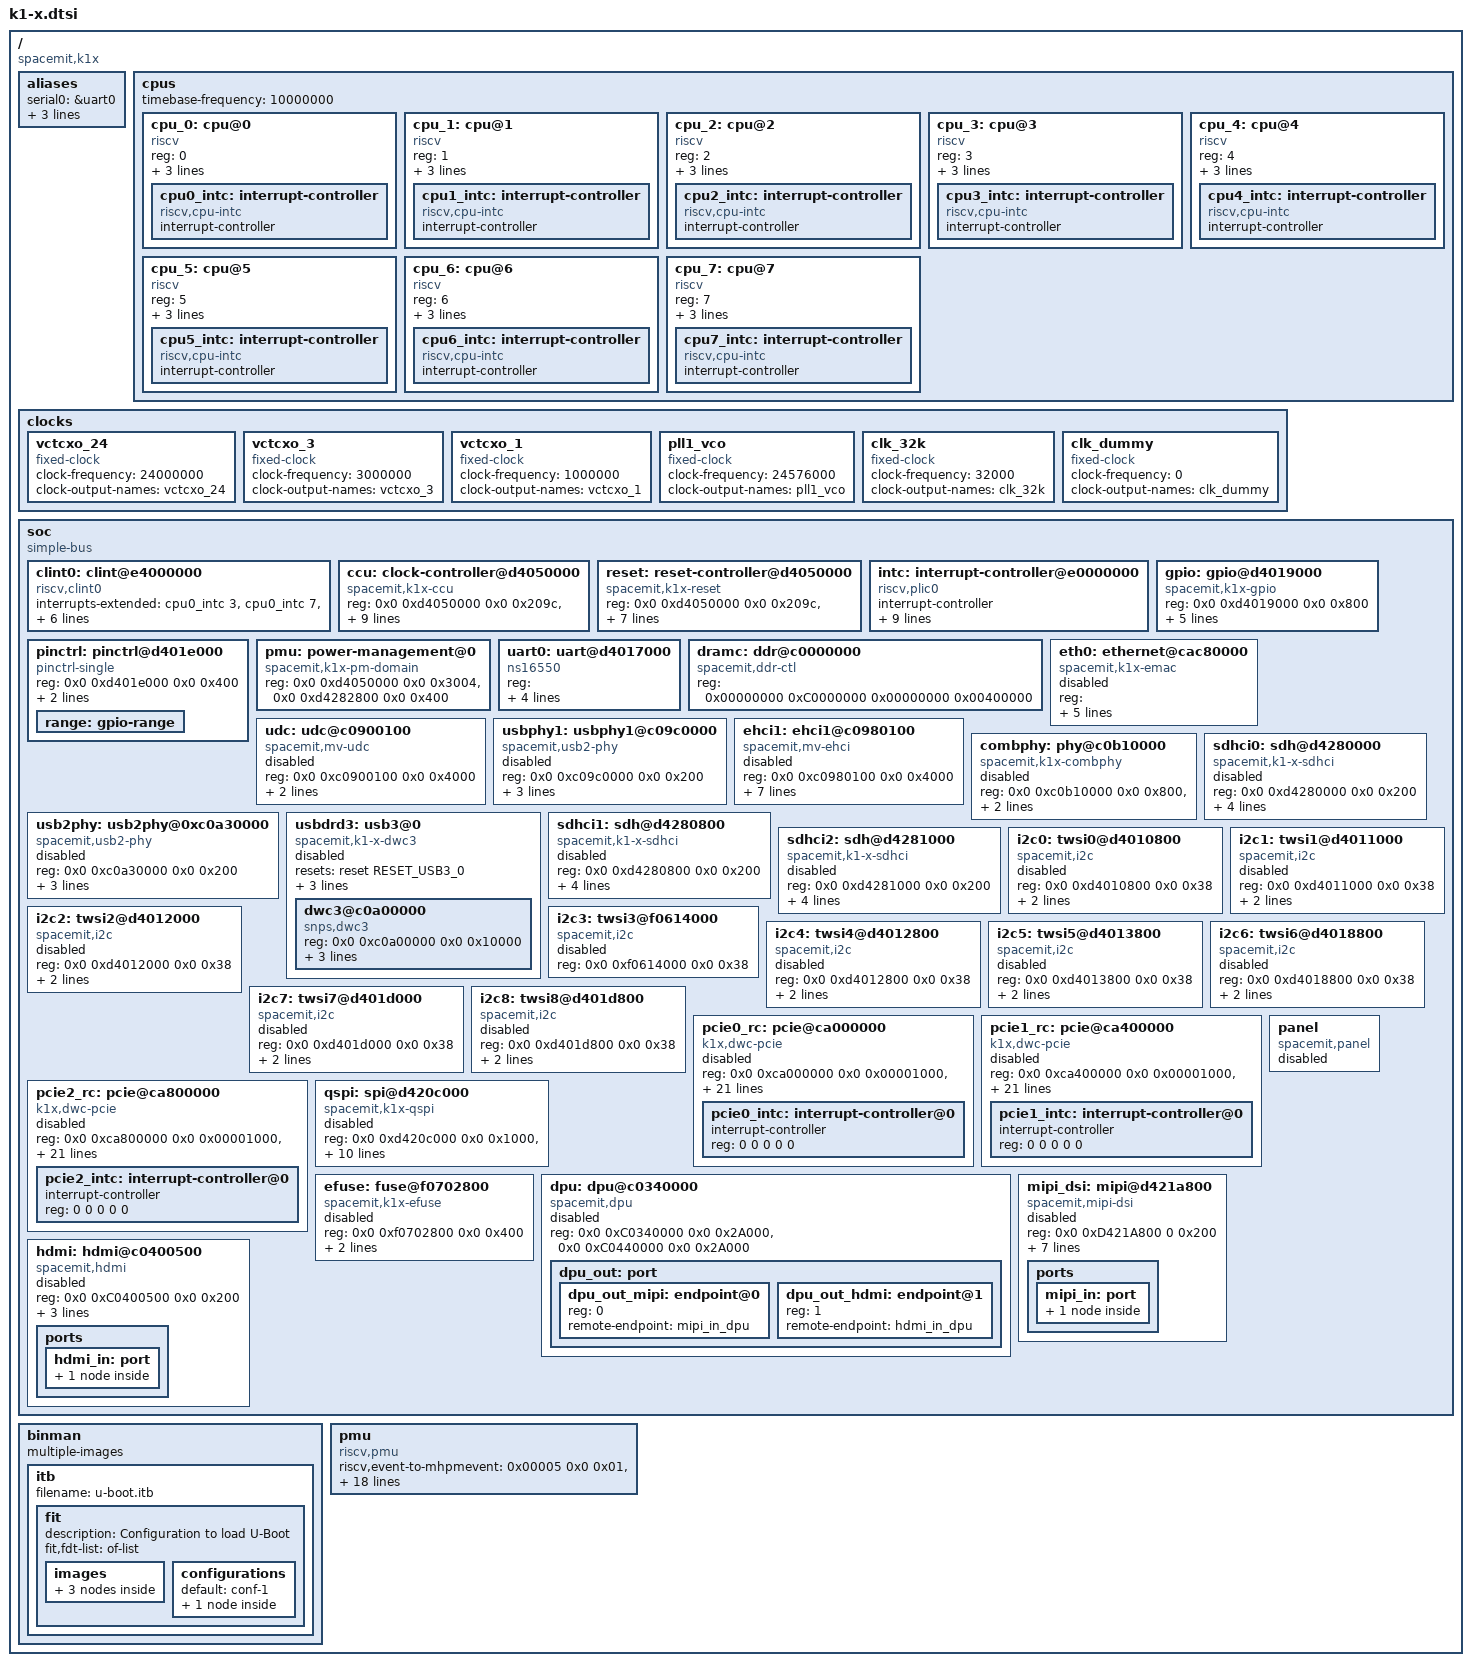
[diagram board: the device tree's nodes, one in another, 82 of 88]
// SPDX-License-Identifier: (GPL-2.0 OR MIT)
/* Copyright (c) 2023 Spacemit, Inc */

/dts-v1/;
#include <dt-bindings/reset/reset-spacemit-k1x.h>
#include <dt-bindings/clock/spacemit-k1x-clock.h>
#include <dt-bindings/power-domain/k1x-pmu.h>
#include <dt-bindings/phy/phy.h>

/ {
	compatible = "spacemit,k1x", "riscv";
	#address-cells = <2>;
	#size-cells = <2>;

	aliases {
		serial0 = &uart0;
		mmc0 = &sdhci0;
		mmc1 = &sdhci1;
		mmc2 = &sdhci2;
	};

	cpus: cpus {
		#address-cells = <1>;
		#size-cells = <0>;
		timebase-frequency = <10000000>;
		cpu_0: cpu@0 {
			compatible = "riscv";
			device_type = "cpu";
			reg = <0>;
			status = "okay";
			riscv,isa = "rv64imafdcvsu_zicsr_zifencei_zicbom_zihintpause_zba_zbb_zbc_zbs_svpbmt_sstc_sscofpmf";
			mmu-type = "riscv,sv39";

			cpu0_intc: interrupt-controller {
				#interrupt-cells = <1>;
				compatible = "riscv,cpu-intc";
				interrupt-controller;
			};
		};
		cpu_1: cpu@1 {
			compatible = "riscv";
			device_type = "cpu";
			reg = <1>;
			status = "okay";
			riscv,isa = "rv64imafdcvsu_zicsr_zifencei_zicbom_zihintpause_zba_zbb_zbc_zbs_svpbmt_sstc_sscofpmf";
			mmu-type = "riscv,sv39";

			cpu1_intc: interrupt-controller {
				#interrupt-cells = <1>;
				compatible = "riscv,cpu-intc";
				interrupt-controller;
			};
		};
		cpu_2: cpu@2 {
			compatible = "riscv";
			device_type = "cpu";
			reg = <2>;
			status = "okay";
			riscv,isa = "rv64imafdcvsu_zicsr_zifencei_zicbom_zihintpause_zba_zbb_zbc_zbs_svpbmt_sstc_sscofpmf";
			mmu-type = "riscv,sv39";

			cpu2_intc: interrupt-controller {
				#interrupt-cells = <1>;
				compatible = "riscv,cpu-intc";
				interrupt-controller;
			};
		};
		cpu_3: cpu@3 {
			compatible = "riscv";
			device_type = "cpu";
			reg = <3>;
			status = "okay";
			riscv,isa = "rv64imafdcvsu_zicsr_zifencei_zicbom_zihintpause_zba_zbb_zbc_zbs_svpbmt_sstc_sscofpmf";
			mmu-type = "riscv,sv39";

			cpu3_intc: interrupt-controller {
				#interrupt-cells = <1>;
				compatible = "riscv,cpu-intc";
				interrupt-controller;
			};
		};
		cpu_4: cpu@4 {
			compatible = "riscv";
			device_type = "cpu";
			reg = <4>;
			status = "okay";
			riscv,isa = "rv64imafdcvsu_zicsr_zifencei_zicbom_zihintpause_zba_zbb_zbc_zbs_svpbmt_sstc_sscofpmf";
			mmu-type = "riscv,sv39";

			cpu4_intc: interrupt-controller {
				#interrupt-cells = <1>;
				compatible = "riscv,cpu-intc";
				interrupt-controller;
			};
		};
		cpu_5: cpu@5 {
			compatible = "riscv";
			device_type = "cpu";
			reg = <5>;
			status = "okay";
			riscv,isa = "rv64imafdcvsu_zicsr_zifencei_zicbom_zihintpause_zba_zbb_zbc_zbs_svpbmt_sstc_sscofpmf";
			mmu-type = "riscv,sv39";

			cpu5_intc: interrupt-controller {
				#interrupt-cells = <1>;
				compatible = "riscv,cpu-intc";
				interrupt-controller;
			};
		};
		cpu_6: cpu@6 {
			compatible = "riscv";
			device_type = "cpu";
			reg = <6>;
			status = "okay";
			riscv,isa = "rv64imafdcvsu_zicsr_zifencei_zicbom_zihintpause_zba_zbb_zbc_zbs_svpbmt_sstc_sscofpmf";
			mmu-type = "riscv,sv39";

			cpu6_intc: interrupt-controller {
				#interrupt-cells = <1>;
				compatible = "riscv,cpu-intc";
				interrupt-controller;
			};
		};
		cpu_7: cpu@7 {
			compatible = "riscv";
			device_type = "cpu";
			reg = <7>;
			status = "okay";
			riscv,isa = "rv64imafdcvsu_zicsr_zifencei_zicbom_zihintpause_zba_zbb_zbc_zbs_svpbmt_sstc_sscofpmf";
			mmu-type = "riscv,sv39";

			cpu7_intc: interrupt-controller {
				#interrupt-cells = <1>;
				compatible = "riscv,cpu-intc";
				interrupt-controller;
			};
		};
	};

	clocks: clocks {
		#address-cells = <0x2>;
		#size-cells = <0x2>;
		ranges;

		vctcxo_24: vctcxo_24 {
			#clock-cells = <0>;
			compatible = "fixed-clock";
			clock-frequency = <24000000>;
			clock-output-names = "vctcxo_24";
		};
		vctcxo_3: vctcxo_3 {
			#clock-cells = <0>;
			compatible = "fixed-clock";
			clock-frequency = <3000000>;
			clock-output-names = "vctcxo_3";
		};
		vctcxo_1: vctcxo_1 {
			#clock-cells = <0>;
			compatible = "fixed-clock";
			clock-frequency = <1000000>;
			clock-output-names = "vctcxo_1";
		};
		pll1_vco: pll1_vco {
			#clock-cells = <0>;
			compatible = "fixed-clock";
			clock-frequency = <24576000>;
			clock-output-names = "pll1_vco";
		};
		clk_32k: clk_32k {
			#clock-cells = <0>;
			compatible = "fixed-clock";
			clock-frequency = <32000>;
			clock-output-names = "clk_32k";
		};
		clk_dummy: clk_dummy {
			#clock-cells = <0>;
			compatible = "fixed-clock";
			clock-frequency = <0>;
			clock-output-names = "clk_dummy";
		};
	};

	soc:soc {
		compatible = "simple-bus";
		#address-cells = <2>;
		#size-cells = <2>;
		ranges;

		clint0: clint@e4000000 {
			compatible = "riscv,clint0";
			interrupts-extended = <
				&cpu0_intc  3 &cpu0_intc  7
				&cpu1_intc  3 &cpu1_intc  7
				&cpu2_intc  3 &cpu2_intc  7
				&cpu3_intc  3 &cpu3_intc  7
				&cpu4_intc  3 &cpu4_intc  7
				&cpu5_intc  3 &cpu5_intc  7
				&cpu6_intc  3 &cpu6_intc  7
				&cpu7_intc  3 &cpu7_intc  7
			>;
			reg = <0x0 0xE4000000 0x0 0x00010000>;
		};

		ccu: clock-controller@d4050000 {
			compatible = "spacemit,k1x-ccu";
			reg = <0x0 0xd4050000 0x0 0x209c>,
				<0x0 0xd4282800 0x0 0x400>,
				<0x0 0xd4015000 0x0 0x1000>,
				<0x0 0xd4090000 0x0 0x1000>,
				<0x0 0xd4282c00 0x0 0x400>,
				<0x0 0xd8440000 0x0 0x98>,
				<0x0 0xc0000000 0x0 0x4280>,
				<0x0 0xf0610000 0x0 0x20>;
			reg-names = "mpmu", "apmu", "apbc", "apbs", "ciu", "dciu", "ddrc", "apbc2";
			clocks = <&vctcxo_24>, <&vctcxo_3>, <&vctcxo_1>, <&pll1_vco>,
				<&clk_32k>, <&clk_dummy>;
			clock-names = "vctcxo_24", "vctcxo_3", "vctcxo_1", "pll1_vco",
				"clk_32k", "clk_dummy";
			#clock-cells = <1>;
			status = "okay";
		};

		reset: reset-controller@d4050000 {
			compatible = "spacemit,k1x-reset";
			reg = <0x0 0xd4050000 0x0 0x209c>,
				<0x0 0xd4282800 0x0 0x400>,
				<0x0 0xd4015000 0x0 0x1000>,
				<0x0 0xd4090000 0x0 0x1000>,
				<0x0 0xd4282c00 0x0 0x400>,
				<0x0 0xd8440000 0x0 0x98>,
				<0x0 0xc0000000 0x0 0x4280>,
				<0x0 0xf0610000 0x0 0x20>;
			reg-names = "mpmu", "apmu", "apbc", "apbs", "ciu", "dciu", "ddrc", "apbc2";
			#reset-cells = <1>;
			status = "okay";
		};

		intc: interrupt-controller@e0000000 {
			#interrupt-cells = <1>;
			compatible = "riscv,plic0";
			interrupt-controller;
			interrupts-extended = <
				&cpu0_intc 11 &cpu0_intc 9
				&cpu1_intc 11 &cpu1_intc 9
				&cpu2_intc 11 &cpu2_intc 9
				&cpu3_intc 11 &cpu3_intc 9
				&cpu4_intc 11 &cpu4_intc 9
				&cpu5_intc 11 &cpu5_intc 9
				&cpu6_intc 11 &cpu6_intc 9
				&cpu7_intc 11 &cpu7_intc 9
			>;
			reg = <0x0 0xE0000000 0x0 0x04000000>;
			reg-names = "control";
			riscv,max-priority = <7>;
			riscv,ndev = <159>;
		};

		gpio: gpio@d4019000 {
			compatible = "spacemit,k1x-gpio";
			reg = <0x0 0xd4019000 0x0 0x800>;
			gpio-controller;
			gpio-count = <128>;
			#gpio-cells = <2>;
			interrupts = <58>;
			clocks = <&ccu CLK_GPIO>;
			interrupt-names = "gpio_mux";
			interrupt-parent = <&intc>;
		};

		pinctrl: pinctrl@d401e000 {
			compatible = "pinctrl-single";
			reg = <0x0 0xd401e000 0x0 0x400>;
			#address-cells = <1>;
			#size-cells = <1>;
			#pinctrl-cells = <2>;
			#gpio-range-cells = <3>;

			pinctrl-single,register-width = <32>;
			pinctrl-single,function-mask = <0xff77>;

			range: gpio-range {
				#pinctrl-single,gpio-range-cells = <3>;
			};
		};

                pmu: power-management@0 {
			compatible = "spacemit,k1x-pm-domain";
			reg = <0x0 0xd4050000 0x0 0x3004>, <0x0 0xd4282800 0x0 0x400>;
			#power-domain-cells = <1>;
                };

		uart0: uart@d4017000 {
			compatible = "ns16550";
			reg = <0x00000000 0xD4017000 0x00000000 0x00000100>;
			reg-shift = <2>;
			reg-io-width = <4>;
			clock-frequency = <14000000>;
		};

		dramc: ddr@c0000000 {
			compatible = "spacemit,ddr-ctl";
			reg = <0x00000000 0xC0000000 0x00000000 0x00400000>;
		};

		eth0: ethernet@cac80000 {
			compatible = "spacemit,k1x-emac";
			reg = <0x00000000 0xCAC80000 0x00000000 0x00000420>;
			ctrl-reg = <0x3e4>;
			dline-reg = <0x3e8>;
			clocks = <&ccu CLK_EMAC0_BUS>;
			clock-names = "emac-clk";
			resets = <&reset RESET_EMAC0>;
			reset-names = "emac-reset";
			status = "disabled";
		};

		udc: udc@c0900100 {
			compatible = "spacemit,mv-udc";
			reg = <0x0 0xc0900100 0x0 0x4000>;
			interrupts = <105>;
			interrupt-parent = <&intc>;
			status = "disabled";
		};

		usbphy1: usbphy1@c09c0000 {
			compatible = "spacemit,usb2-phy";
			reg = <0x0 0xc09c0000 0x0 0x200>;
			spacemit,phy-name = "mv-usb-phy";
			spacemit,pll-lock-bypass;
			clocks = <&ccu CLK_USB_P1>;
			#phy-cells = <0>;
			status = "disabled";
		};

		ehci1: ehci1@c0980100 {
			compatible = "spacemit,mv-ehci";
			reg = <0x0 0xc0980100 0x0 0x4000>;
			interrupts = <118>;
			interrupt-parent = <&intc>;
			spacemit,ehci-name = "mv-ehci";
			spacemit,otg-force-a-bus-req;
			resets = <&reset RESET_USBP1_AXI>;
			clocks = <&ccu CLK_USB_P1>;
			phys = <&usbphy1>;
			status = "disabled";
		};

		combphy: phy@c0b10000{
			compatible = "spacemit,k1x-combphy";
			reg = <0x0 0xc0b10000 0x0 0x800>,
				  <0x0 0xd4282910 0x0 0x400>;
			reg-names = "puphy", "phy_sel";
			resets = <&reset RESET_PCIE0>;
			reset-names = "phy_rst";
			#phy-cells = <1>;
			status = "disabled";
		};

		usb2phy: usb2phy@0xc0a30000 {
			compatible = "spacemit,usb2-phy";
			reg = <0x0 0xc0a30000  0x0 0x200>;
			spacemit,phy-name = "mv-usb-phy";
			spacemit,pll-lock-bypass;
			clocks = <&ccu CLK_USB30>;
			#phy-cells = <0>;
			status = "disabled";
		};

		usbdrd3: usb3@0 {
			compatible = "spacemit,k1-x-dwc3";
			#address-cells = <2>;
			#size-cells = <2>;
			resets = <&reset RESET_USB3_0>;
			reset-names = "ctl_rst";
			clocks = <&ccu CLK_USB30>;
			clock-names = "usbdrd30";
			interrupt-parent = <&intc>;
			interrupts = <149>;
			ranges;
			status = "disabled";

			dwc3@c0a00000 {
				compatible = "snps,dwc3";
				reg = <0x0 0xc0a00000 0x0 0x10000>;
				interrupt-parent = <&intc>;
				interrupts = <125>;
				phys = <&combphy PHY_TYPE_USB3>, <&usb2phy>;
				phy-names = "usb3-phy", "usb2-phy";
			};
		};

		sdhci0: sdh@d4280000 {
			compatible = "spacemit,k1-x-sdhci";
			reg = <0x0 0xd4280000 0x0 0x200>;
			interrupt-parent = <&intc>;
			interrupts = <99>;
			resets = <&reset RESET_SDH_AXI>,
					 <&reset RESET_SDH0>;
			reset-names = "sdh_axi", "sdh0";
			clocks = <&ccu CLK_SDH0>,
					 <&ccu CLK_SDH_AXI>;
			clock-names = "sdh-io", "sdh-core";
			status = "disabled";
		};

		sdhci1: sdh@d4280800 {
			compatible = "spacemit,k1-x-sdhci";
			reg = <0x0 0xd4280800 0x0 0x200>;
			interrupt-parent = <&intc>;
			interrupts = <100>;
			resets = <&reset RESET_SDH_AXI>,
					 <&reset RESET_SDH1>;
			reset-names = "sdh_axi", "sdh1";
			clocks = <&ccu CLK_SDH1>,
					 <&ccu CLK_SDH_AXI>;
			clock-names = "sdh-io", "sdh-core";
			status = "disabled";
		};

		sdhci2: sdh@d4281000 {
			compatible = "spacemit,k1-x-sdhci";
			reg = <0x0 0xd4281000 0x0 0x200>;
			interrupt-parent = <&intc>;
			interrupts = <101>;
			resets = <&reset RESET_SDH_AXI>,
					 <&reset RESET_SDH2>;
			reset-names = "sdh_axi", "sdh2";
			clocks = <&ccu CLK_SDH2>,
					 <&ccu CLK_SDH_AXI>;
			clock-names = "sdh-io", "sdh-core";
			status = "disabled";
		};

                i2c0: twsi0@d4010800 {
			compatible = "spacemit,i2c";
			reg = <0x0 0xd4010800 0x0 0x38>;
			clocks = <&ccu CLK_TWSI0>;
			resets = <&reset RESET_TWSI0>;
			#address-cells = <1>;
			#size-cells = <0>;
			status = "disabled";
                };

                i2c1: twsi1@d4011000 {
			compatible = "spacemit,i2c";
			reg = <0x0 0xd4011000 0x0 0x38>;
			clocks = <&ccu CLK_TWSI1>;
			resets = <&reset RESET_TWSI1>;
			#address-cells = <1>;
			#size-cells = <0>;
			status = "disabled";
                };

                i2c2: twsi2@d4012000 {
			compatible = "spacemit,i2c";
			reg = <0x0 0xd4012000 0x0 0x38>;
			clocks = <&ccu CLK_TWSI2>;
			resets = <&reset RESET_TWSI2>;
			#address-cells = <1>;
			#size-cells = <0>;
			status = "disabled";
                };

                i2c3: twsi3@f0614000 {
			compatible = "spacemit,i2c";
			reg = <0x0 0xf0614000 0x0 0x38>;
			#address-cells = <1>;
			#size-cells = <0>;
			status = "disabled";
                };

                i2c4: twsi4@d4012800 {
			compatible = "spacemit,i2c";
			reg = <0x0 0xd4012800 0x0 0x38>;
			clocks = <&ccu CLK_TWSI4>;
			resets = <&reset RESET_TWSI4>;
			#address-cells = <1>;
			#size-cells = <0>;
			status = "disabled";
                };

                i2c5: twsi5@d4013800 {
			compatible = "spacemit,i2c";
			reg = <0x0 0xd4013800 0x0 0x38>;
			clocks = <&ccu CLK_TWSI5>;
			resets = <&reset RESET_TWSI5>;
			#address-cells = <1>;
			#size-cells = <0>;
			status = "disabled";
                };

                i2c6: twsi6@d4018800 {
			compatible = "spacemit,i2c";
			reg = <0x0 0xd4018800 0x0 0x38>;
			clocks = <&ccu CLK_TWSI6>;
			resets = <&reset RESET_TWSI6>;
			#address-cells = <1>;
			#size-cells = <0>;
			status = "disabled";
                };

                i2c7: twsi7@d401d000 {
			compatible = "spacemit,i2c";
			reg = <0x0 0xd401d000 0x0 0x38>;
			clocks = <&ccu CLK_TWSI7>;
			resets = <&reset RESET_TWSI7>;
			#address-cells = <1>;
			#size-cells = <0>;
			status = "disabled";
                };

                i2c8: twsi8@d401d800 {
			compatible = "spacemit,i2c";
			reg = <0x0 0xd401d800 0x0 0x38>;
			clocks = <&ccu CLK_TWSI8>;
			resets = <&reset RESET_TWSI8>;
			#address-cells = <1>;
			#size-cells = <0>;
			status = "disabled";
                };

		pcie0_rc: pcie@ca000000 {
			compatible = "k1x,dwc-pcie";
			reg = <0x0 0xca000000 0x0 0x00001000>, /* dbi */
			      <0x0 0xca300000 0x0 0x0001ff24>, /* atu registers */
			      <0x0 0x80000000 0x0 0x00100000>, /* config space */
			      <0x0 0xd4282bcc 0x0 0x00000008>, /* k1x soc config addr */
			      <0x0 0xc0b20000 0x0 0x00001000>, /* phy ahb */
			      <0x0 0xc0b10000 0x0 0x00001000>, /* phy addr */
			      <0x0 0xd4282bcc 0x0 0x00000008>, /* conf0 addr */
			      <0x0 0xc0b10000 0x0 0x00001000>; /* phy0 addr */
			reg-names = "dbi", "atu", "config", "k1x_conf", "phy_ahb", "phy_addr", "conf0_addr", "phy0_addr";

			k1x,pcie-port = <0>;
			clocks = <&ccu CLK_PCIE0>;
			clock-names = "pcie-clk";
			resets = <&reset RESET_PCIE0>;
			reset-names = "pcie-reset";

			bus-range = <0x00 0xff>;
			max-link-speed = <2>;
			num-lanes = <1>;
			num-viewport = <8>;
			device_type = "pci";
			#address-cells = <3>;
			#size-cells = <2>;
			ranges = <0x81000000 0x0 0x80100000 0 0x80100000 0x0 0x100000>,
				 <0x82000000 0x0 0x80200000 0 0x80200000 0x0 0x0fe00000>;

			interrupts = <141>, <145>;
			interrupt-parent = <&intc>;
			#interrupt-cells = <1>;
			interrupt-map-mask = <0 0 0 0x7>;
			interrupt-map = <0000 0 0 1 &pcie0_intc 1>, /* int_a */
					<0000 0 0 2 &pcie0_intc 2>, /* int_b */
					<0000 0 0 3 &pcie0_intc 3>, /* int_c */
					<0000 0 0 4 &pcie0_intc 4>; /* int_d */
			linux,pci-domain = <0>;
			status = "disabled";
			pcie0_intc: interrupt-controller@0 {
				interrupt-controller;
				reg = <0 0 0 0 0>;
				#address-cells = <0>;
				#interrupt-cells = <1>;
			};
		};

		pcie1_rc: pcie@ca400000 {
			compatible = "k1x,dwc-pcie";
			reg = <0x0 0xca400000 0x0 0x00001000>, /* dbi */
			      <0x0 0xca700000 0x0 0x0001ff24>, /* atu registers */
			      <0x0 0x90000000 0x0 0x00100000>, /* config space */
			      <0x0 0xd4282bd4 0x0 0x00000008>, /* k1x soc config addr */
			      <0x0 0xc0c20000 0x0 0x00001000>, /* phy ahb */
			      <0x0 0xc0c10000 0x0 0x00001000>, /* phy addr */
			      <0x0 0xd4282bcc 0x0 0x00000008>, /* conf0 addr */
			      <0x0 0xc0b10000 0x0 0x00001000>; /* phy0 addr */
			reg-names = "dbi", "atu", "config", "k1x_conf", "phy_ahb", "phy_addr", "conf0_addr", "phy0_addr";

			k1x,pcie-port = <1>;
			clocks = <&ccu CLK_PCIE1>;
			clock-names = "pcie-clk";
			resets = <&reset RESET_PCIE1>;
			reset-names = "pcie-reset";

			bus-range = <0x00 0xff>;
			max-link-speed = <2>;
			num-lanes = <2>;
			num-viewport = <8>;
			device_type = "pci";
			#address-cells = <3>;
			#size-cells = <2>;
			ranges = <0x01000000 0x0 0x90100000 0 0x90100000 0x0 0x100000>,
				 <0x02000000 0x0 0x90200000 0 0x90200000 0x0 0x0fe00000>;

			interrupts = <142>, <146>;
			interrupt-parent = <&intc>;
			#interrupt-cells = <1>;
			interrupt-map-mask = <0 0 0 0x7>;
			interrupt-map = <0000 0 0 1 &pcie1_intc 1>, /* int_a */
					<0000 0 0 2 &pcie1_intc 2>, /* int_b */
					<0000 0 0 3 &pcie1_intc 3>, /* int_c */
					<0000 0 0 4 &pcie1_intc 4>; /* int_d */
			linux,pci-domain = <1>;
			status = "disabled";
			pcie1_intc: interrupt-controller@0 {
				interrupt-controller;
				reg = <0 0 0 0 0>;
				#address-cells = <0>;
				#interrupt-cells = <1>;
			};
		};

		pcie2_rc: pcie@ca800000 {
			compatible = "k1x,dwc-pcie";
			reg = <0x0 0xca800000 0x0 0x00001000>, /* dbi */
			      <0x0 0xcab00000 0x0 0x0001ff24>, /* atu registers */
			      <0x0 0xa0000000 0x0 0x00100000>, /* config space */
			      <0x0 0xd4282bdc 0x0 0x00000008>, /* k1x soc config addr */
			      <0x0 0xc0d20000 0x0 0x00001000>, /* phy ahb */
			      <0x0 0xc0d10000 0x0 0x00001000>, /* phy addr */
			      <0x0 0xd4282bcc 0x0 0x00000008>, /* conf0 addr */
			      <0x0 0xc0b10000 0x0 0x00001000>; /* phy0 addr */
			reg-names = "dbi", "atu", "config", "k1x_conf", "phy_ahb", "phy_addr", "conf0_addr", "phy0_addr";

			k1x,pcie-port = <2>;
			clocks = <&ccu CLK_PCIE2>;
			clock-names = "pcie-clk";
			resets = <&reset RESET_PCIE2>;
			reset-names = "pcie-reset";

			bus-range = <0x00 0xff>;
			max-link-speed = <2>;
			num-lanes = <2>;
			num-viewport = <8>;
			device_type = "pci";
			#address-cells = <3>;
			#size-cells = <2>;
			ranges = <0x01000000 0x0 0xa0100000 0 0xa0100000 0x0 0x100000>,
				 <0x02000000 0x0 0xa0200000 0 0xa0200000 0x0 0x16000000>;

			interrupts = <143>, <147>;
			interrupt-parent = <&intc>;
			#interrupt-cells = <1>;
			interrupt-map-mask = <0 0 0 0x7>;
			interrupt-map = <0000 0 0 1 &pcie2_intc 1>, /* int_a */
					<0000 0 0 2 &pcie2_intc 2>, /* int_b */
					<0000 0 0 3 &pcie2_intc 3>, /* int_c */
					<0000 0 0 4 &pcie2_intc 4>; /* int_d */
			linux,pci-domain = <2>;
			status = "disabled";
			pcie2_intc: interrupt-controller@0 {
				interrupt-controller;
				reg = <0 0 0 0 0>;
				#address-cells = <0>;
				#interrupt-cells = <1>;
			};
		};

		qspi: spi@d420c000 {
			compatible = "spacemit,k1x-qspi";
			#address-cells = <1>;
			#size-cells = <0>;
			reg = <0x0 0xd420c000 0x0 0x1000>,
			      <0x0 0xb8000000 0x0 0xd00000>;
			reg-names = "qspi-base", "qspi-mmap";
			qspi-sfa1ad = <0xa00000>;
			qspi-sfa2ad = <0xb00000>;
			qspi-sfb1ad = <0xc00000>;
			qspi-sfb2ad = <0xd00000>;
			clocks = <&ccu CLK_QSPI>,
				<&ccu CLK_QSPI_BUS>;
			clock-names = "qspi_clk", "qspi_bus_clk";
			resets = <&reset RESET_QSPI>,
				<&reset RESET_QSPI_BUS>;
			reset-names = "qspi_reset", "qspi_bus_reset";
			qspi-pmuap-reg = <0xd4282860>;
			spi-max-frequency = <26500000>;
			qspi-id = <4>;
			status = "disabled";
		};

		efuse: fuse@f0702800 {
			compatible = "spacemit,k1x-efuse";
			reg = <0x0 0xf0702800 0x0 0x400>;
			resets = <&reset RESET_AES>;
			reset-names = "aes_reset";
			clocks = <&ccu CLK_AES>;
			clock-names = "aes_core";
			status = "disabled";
		};

		dpu: dpu@c0340000 {
			compatible = "spacemit,dpu";
			reg = <0x0 0xC0340000 0x0 0x2A000>,
				  <0x0 0xC0440000 0x0 0x2A000>;
			reg-names = "dsi", "hdmi";
			status = "disabled";

			dpu_out: port {
				#address-cells = <1>;
				#size-cells = <0>;

				dpu_out_mipi: endpoint@0 {
					reg = <0>;
					remote-endpoint = <&mipi_in_dpu>;
				};

				dpu_out_hdmi: endpoint@1 {
					reg = <1>;
					remote-endpoint = <&hdmi_in_dpu>;
				};
			};
		};

		mipi_dsi: mipi@d421a800 {
			compatible = "spacemit,mipi-dsi";
			reg = <0x0 0xD421A800 0 0x200>;
			reg-names = "dsi";

			clocks = <&ccu CLK_DPU_PXCLK>,
				<&ccu CLK_DPU_MCLK>,
				<&ccu CLK_DPU_HCLK>,
				<&ccu CLK_DPU_ESC>,
				<&ccu CLK_DPU_BIT>;
			clock-names = "pxclk", "mclk", "hclk", "escclk", "bitclk";
			resets = <&reset RESET_MIPI>,
				<&reset RESET_LCD_MCLK>,
				<&reset RESET_DSI_ESC>,
				<&reset RESET_LCD>;
			reset-names= "dsi_reset", "mclk_reset", "esc_reset", "lcd_reset";
			power-domains = <&pmu K1X_PMU_LCD_PWR_DOMAIN>;

			status = "disabled";

			ports {
				mipi_in: port {
					#address-cells = <1>;
					#size-cells = <0>;
					mipi_in_dpu: endpoint@0 {
						reg = <0>;
						remote-endpoint = <&dpu_out_mipi>;
					};
				};
			};
		};

		panel: panel {
			  compatible = "spacemit,panel";
			  status = "disabled";
		};

		hdmi: hdmi@c0400500 {
			compatible = "spacemit,hdmi";
			reg = <0x0 0xC0400500 0x0 0x200>;
			reg-names = "hdmi";
			clocks = <&ccu CLK_HDMI>;
			clock-names = "hmclk";
			resets = <&reset RESET_HDMI>;
			reset-names= "hdmi_reset";
			power-domains = <&pmu K1X_PMU_HDMI_PWR_DOMAIN>;
			status = "disabled";

			ports {
				hdmi_in: port {
					#address-cells = <1>;
					#size-cells = <0>;
					hdmi_in_dpu: endpoint@0 {
						reg = <0>;
						remote-endpoint = <&dpu_out_hdmi>;
					};
				};
			};
		};

	};

	binman: binman {
		multiple-images;
		itb {
			filename = "u-boot.itb";

			fit {
				description = "Configuration to load U-Boot";
				#address-cells = <2>;
				fit,fdt-list = "of-list";

				images {
					uboot {
						description = "U-Boot";
						type = "standalone";
						os = "U-Boot";
						arch = "riscv";
						compression = "none";
						load = <CONFIG_SYS_TEXT_BASE>;

						uboot_blob: blob-ext {
							filename = "u-boot-nodtb.bin";
						};
					};

					@fdt-SEQ {
						description = "NAME";
						type = "flat_dt";
						compression = "none";
					};
				};

				configurations {
					default = "conf-1";

					@conf-SEQ {
						description = "U-boot FIT config";
						loadables = "uboot";
						fdt = "fdt-SEQ";
					};
				};
			};
		};
	};

	pmu {
		compatible = "riscv,pmu";

		riscv,event-to-mhpmevent =
			/* BRANCH_INSTRUCTIONS */
			<0x00005 0x0 0x01>,
			/* BRANCH_MISSES */
			<0x00006 0x0 0x02>,
			/* STALLED_CYCLES_FRONTEND */
			<0x00008 0x0 0x03>,
			/* STALLED_CYCLES_BACKEND */
			<0x00009 0x0 0x04>,
			/* L1D_READ_ACCESS */
			<0x10000 0x0 0x06>,
			/* L1D_READ_MISS */
			<0x10001 0x0 0x05>,
			/* L1D_WRITE_ACCESS */
			<0x10002 0x0 0x0a>,
			/* L1D_WRITE_MISS */
			<0x10003 0x0 0x09>,
			/* L1I_READ_ACCESS */
			<0x10008 0x0 0x0c>,
			/* L1I_READ_MISS */
			<0x10009 0x0 0x0b>,
			/* L1I_PREFETCH_ACCESS */
			<0x1000c 0x0 0x0e>,
			/* L1I_PREFETCH_MISS */
			<0x1000d 0x0 0x0d>,
			/* DTLB_READ_MISS */
			<0x10019 0x0 0x15>,
			/* DTLB_WRITE_MISS */
			<0x1001b 0x0 0x19>,
			/* ITLB_READ_MISS */
			<0x10021 0x0 0x1b>;

		/* 16 valid counters: mhpmcounter3 ~ mhpmcounter18 */
		riscv,event-to-mhpmcounters =
			<0x00005 0x00006 0x0007fff8>,
			<0x00008 0x00009 0x0007fff8>,
			<0x10000 0x10003 0x0007fff8>,
			<0x10008 0x10009 0x0007fff8>,
			<0x1000c 0x1000d 0x0007fff8>,
			<0x10019 0x10019 0x0007fff8>,
			<0x1001b 0x1001b 0x0007fff8>,
			<0x10021 0x10021 0x0007fff8>;

		riscv,raw-event-to-mhpmcounters =
			/*
			 * For convenience, we treat 0x1~0xff as valid indexes,
			 * but actually in hardware the valid indexes are 0x1~0xbd.
			 */
			<0x0 0x0 0xffffffff 0xffffff00 0x0007fff8>;
	};
};
